# GD32A71x register map
File version: 1.0
CPU: CM7 r2p1, little endian, MPU, FPU, DSP, 4 interrupt priority bits
Registers are 32-bit, read-write, reset 0x0 unless marked. A register's access mark holds for its fields unless they carry their own. Offsets are from the block's base; [hi:lo] are bit positions; {n}, {i} and the like mark numbered series; 'fields as' and 'values as' point back to an identical list.

## BKP — Backup registers
Base 0x40006C00
{0x4+4i} DATA{i} (i=0..9) — Backup data register {i}
  [15:0] DATA — Backup data
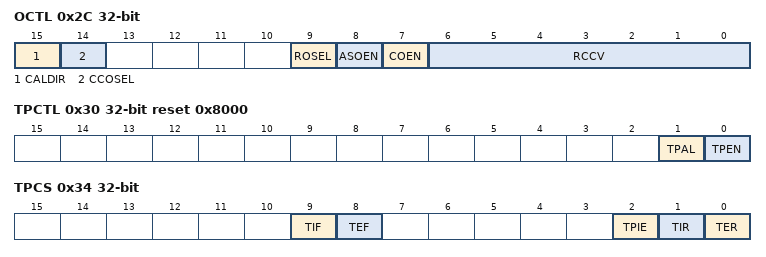
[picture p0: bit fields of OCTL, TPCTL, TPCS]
0x2C OCTL — RTC signal output control register
  [15] CALDIR — RTC clock calibration direction
  [14] CCOSEL — RTC clock output selection
  [9] ROSEL — RTC output selection
  [8] ASOEN — RTC alarm or second signal output enable
  [7] COEN — RTC clock calibration output enable
  [6:0] RCCV — RTC clock calibration value
0x30 TPCTL reset 0x8000 — Tamper pin control register
  [1] TPAL — TAMPER pin active level
  [0] TPEN — TAMPER detection enable
0x34 TPCS access per field — Tamper control and status register
  [9] TIF ro — Tamper interrupt flag
  [8] TEF ro — Tamper event flag
  [2] TPIE rw — Tamper interrupt enable
  [1] TIR wo — Tamper interrupt reset
  [0] TER wo — Tamper event reset

## BUSIM — Bus interconnect matrix
Base 0x49009000
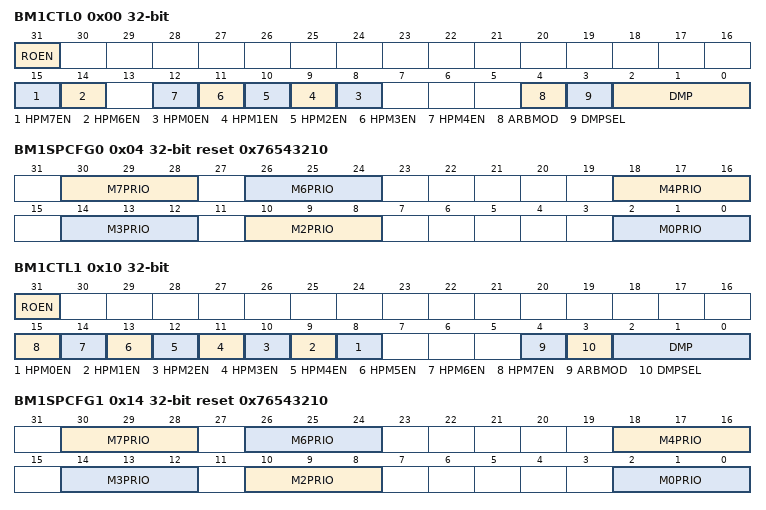
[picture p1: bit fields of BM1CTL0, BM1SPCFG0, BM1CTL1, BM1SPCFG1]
0x00 BM1CTL0 — BM1 contorl register
  [31] ROEN — Register read-only enable
  [15] HPM7EN — High priority mode for master port 7 enable bit
  [14] HPM6EN — High priority mode for master port 6 enable bit
  [n+8] HPM{n}EN (n=0..4) — High priority mode for master port {n} enable bit
  [4] ARBMOD — Arbitration mode select
  [3] DMPSEL — Default master port strategy select
  [2:0] DMP — Default master port
0x04 BM1SPCFG0 reset 0x76543210 — Slave port priority configuration register
  [30:28] M7PRIO — Priority of master port 7
  [26:24] M6PRIO — Priority of master port 6
  [18:16] M4PRIO — Priority of master port 4
  [14:12] M3PRIO — Priority of master port 3
  [10:8] M2PRIO — Priority of master port 2
  [2:0] M0PRIO — Priority of master port 0
0x10 BM1CTL1 — BM1 contorl register
  [31] ROEN — Register read-only enable
  [n+8] HPM{n}EN (n=0..7) — High priority mode for master port {n} enable bit
  [4] ARBMOD — Arbitration mode select
  [3] DMPSEL — Default master port strategy select
  [2:0] DMP — Default master port
0x14 BM1SPCFG1 reset 0x76543210 — Slave port priority configuration register
  fields as BM1SPCFG0
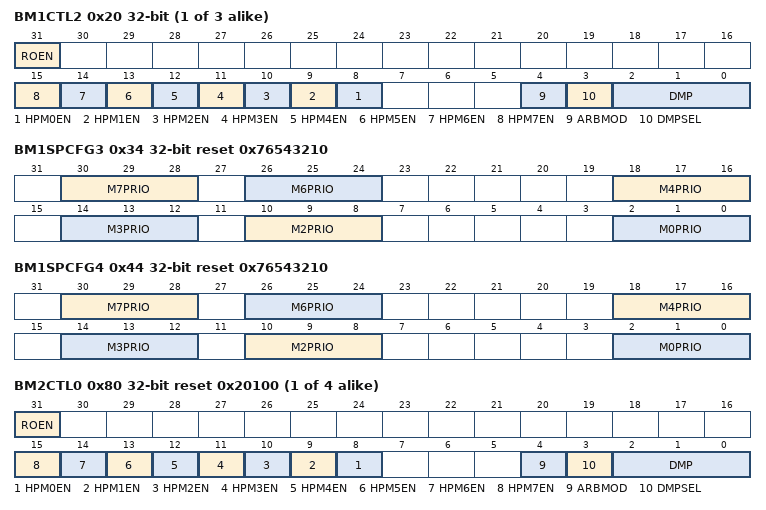
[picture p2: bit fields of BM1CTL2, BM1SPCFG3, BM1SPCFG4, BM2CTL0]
{0x0+0x10*i} BM1CTL{i} (i=2..4) — BM2 contorl register
  fields as BM1CTL1
0x34 BM1SPCFG3 reset 0x76543210 — Slave port priority configuration register
  fields as BM1SPCFG0
0x44 BM1SPCFG4 reset 0x76543210 — Slave port priority configuration register
  fields as BM1SPCFG0
{0x80+0x10*i} BM2CTL{i} reset 0x20100 (i=0..3) — BM2 contorl register
  fields as BM1CTL1
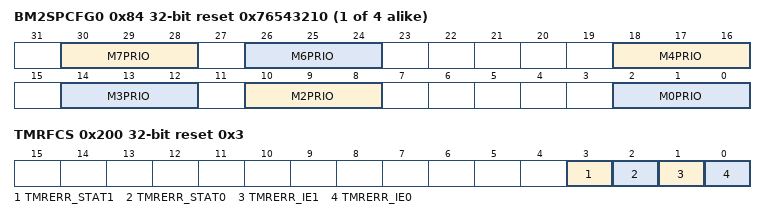
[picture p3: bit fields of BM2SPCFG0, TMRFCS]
{0x84+0x10*i} BM2SPCFG{i} reset 0x76543210 (i=0..3) — Slave port priority configuration register
  fields as BM1SPCFG0
0x200 TMRFCS reset 0x3 — TMR fault control and status register
  [3] TMRERR_STAT1 — IMICU enable register TMR error status
  [2] TMRERR_STAT0 — EXTMPU enable register TMR error status
  [1] TMRERR_IE1 — TMR error 1 (IMICU) output to FMU enable
  [0] TMRERR_IE0 — TMR error 0 (EXTMPU) output to FMU enable

## CMP0 — Comparator
Base 0x40017C00
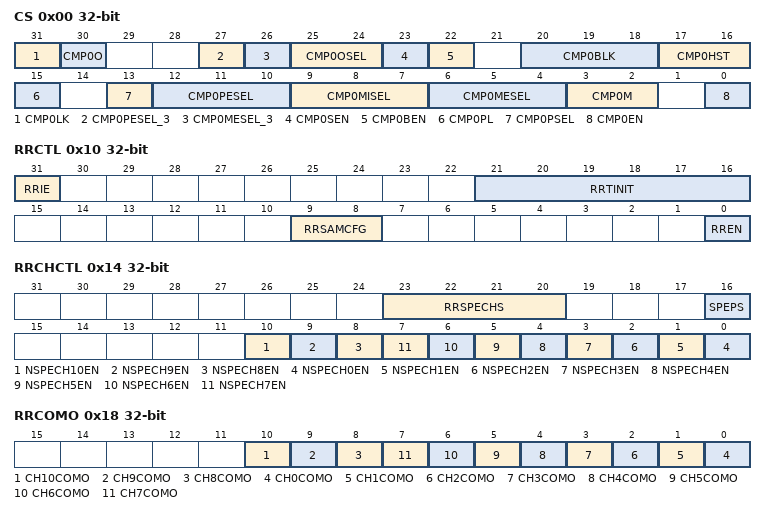
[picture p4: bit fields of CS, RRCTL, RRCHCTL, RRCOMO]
0x00 CS access per field — CMP0 Control / status register
  [31] CMP0LK rw — CMP0 lock
  [30] CMP0O ro — CMP0 output state
  [27] CMP0PESEL_3 rw — cmp0_ip external input selection bit 3
  [26] CMP0MESEL_3 rw — cmp0_im external input selection bit 3
  [25:24] CMP0OSEL rw — CMP0 output selection
  [23] CMP0SEN rw — Voltage scaler enable bit
  [22] CMP0BEN rw — Scaler bridge enable bit
  [20:18] CMP0BLK rw — CMP0 output blanking source
  [17:16] CMP0HST rw — CMP0 hysteresis
  [15] CMP0PL rw — Polarity of CMP0 output
  [13] CMP0PSEL rw — CMP0_IP input selection
  [12:10] CMP0PESEL rw — CMP0_IP external input selection
  [9:7] CMP0MISEL rw — CMP0_IM internal input selection
  [6:4] CMP0MESEL rw — CMP0_IM external input selection
  [3:2] CMP0M rw — CMP0 mode
  [0] CMP0EN rw — CMP0 enable
0x10 RRCTL — Round Robin control register
  [31] RRIE — Interrupt enable for Round-Robin
  [21:16] RRTINIT — Round-Robin time initialization
  [9:8] RRSAMCFG — Round-Robin sample clocks configuration
  [0] RREN — Round-Robin enable
0x14 RRCHCTL — Round Robin channel control register
  [23:20] RRSPECHS — Round-Robin specified channel selection
  [16] SPEPS — Specified port selection
  [10] NSPECH10EN — non-specified mux port channel 10 enable (only for cmp0)
  [9] NSPECH9EN — non-specified mux port channel 9 enable (only for cmp0)
  [8] NSPECH8EN — non-specified mux port channel 8 enable (only for cmp0)
  [n] NSPECH{n}EN (n=0..7) — Non-specified mux port channel {n} enable
0x18 RRCOMO — Round Robin compare output register
  [10] CH10COMO — channel 10 compare output state (only for cmp0)
  [9] CH9COMO — channel 9 compare output state (only for cmp0)
  [8] CH8COMO — channel 8 compare output state (only for cmp0)
  [n] CH{n}COMO (n=0..7) — Channel {n} compare output state
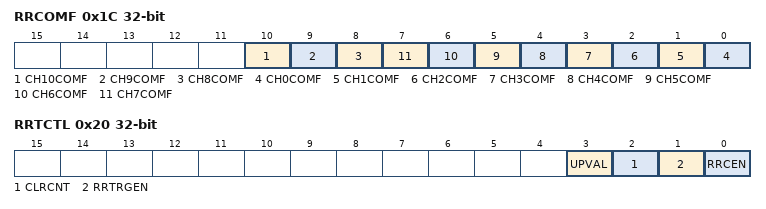
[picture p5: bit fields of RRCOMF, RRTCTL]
0x1C RRCOMF — Round Robin compare result flag register
  [10] CH10COMF — channel 10 compare result flag (only for cmp0)
  [9] CH9COMF — channel 9 compare result flag (only for cmp0)
  [8] CH8COMF — channel 8 compare result flag (only for cmp0)
  [n] CH{n}COMF (n=0..7) — Channel {n} compare result flag
0x20 RRTCTL — Round Robin timer control register
  [3] UPVAL — Write 1 to update the RRTVAL[31:0] value
  [2] CLRCNT — Write 1 to clear the RRCNT[31:0] value
  [1] RRTRGEN — Round Robin trigger enable
  [0] RRCEN — Round Robin counter enable
0x24 RRTTRGV — Round Robin timer trigger value register
  [31:0] RRTVAL — Round Robin timer trigger value
0x28 RRTCNT ro — Round Robin timer counter register
  [31:0] RRCNT — Round Robin timer count
